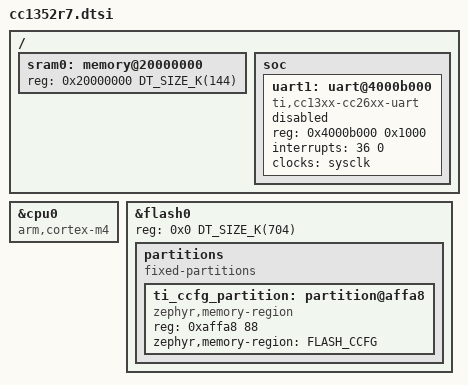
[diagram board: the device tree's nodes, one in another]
/*
 * Copyright (c) 2019 Brett Witherspoon
 *
 * SPDX-License-Identifier: Apache-2.0
 */

#include <mem.h>
#include <ti/cc13xx_cc26xx.dtsi>

/ {
	sram0: memory@20000000 {
		reg = <0x20000000 DT_SIZE_K(144)>;
	};

	soc {
		uart1: uart@4000b000 {
			compatible = "ti,cc13xx-cc26xx-uart";
			reg = <0x4000b000 0x1000>;
			interrupts = <36 0>;
			clocks = <&sysclk>;
			status = "disabled";
		};
	};
};

&cpu0 {
	compatible = "arm,cortex-m4";
};

&flash0 {
	reg = <0x0 DT_SIZE_K(704)>;

	partitions {
		compatible = "fixed-partitions";
		#address-cells = <1>;
		#size-cells = <1>;

		/* CCFG registers occupy the last 88 bytes of flash */
		ti_ccfg_partition: partition@affa8 {
			compatible = "zephyr,memory-region";
			reg = <0xaffa8 88>;
			zephyr,memory-region = "FLASH_CCFG";
		};
	};
};
